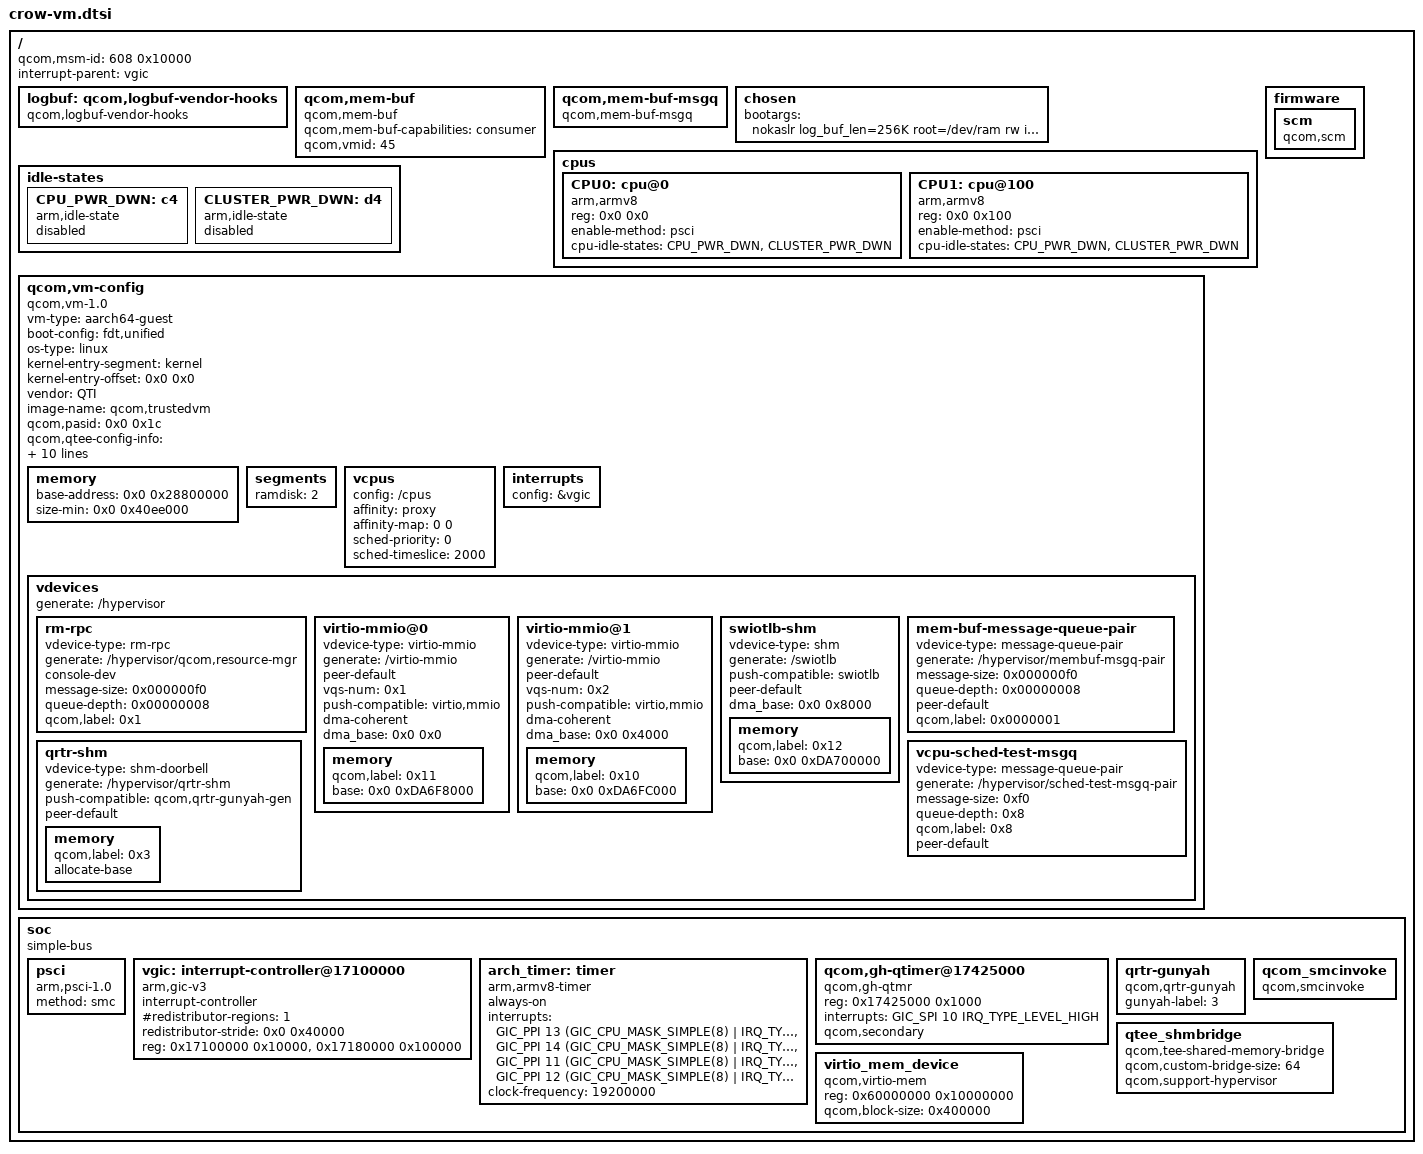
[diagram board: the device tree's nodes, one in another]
#include <dt-bindings/interrupt-controller/arm-gic.h>
#include <dt-bindings/clock/qcom,gcc-crow.h>
#include <dt-bindings/clock/qcom,rpmh.h>

/ {
	#address-cells = <0x2>;
	#size-cells = <0x2>;
	qcom,msm-id = <608 0x10000>;
	interrupt-parent = <&vgic>;

	logbuf: qcom,logbuf-vendor-hooks {
		compatible = "qcom,logbuf-vendor-hooks";
	};

	qcom,mem-buf {
		compatible = "qcom,mem-buf";
		qcom,mem-buf-capabilities = "consumer";
		qcom,vmid = <45>;
	};

	qcom,mem-buf-msgq {
		compatible = "qcom,mem-buf-msgq";
	};

	chosen {
		bootargs = "nokaslr log_buf_len=256K root=/dev/ram rw init=/init console=hvc0 loglevel=8";
	};

	cpus {
		#address-cells = <0x2>;
		#size-cells = <0x0>;

		CPU0: cpu@0 {
			compatible = "arm,armv8";
			reg = <0x0 0x0>;
			device_type = "cpu";
			enable-method = "psci";
			cpu-idle-states = <&CPU_PWR_DWN
					   &CLUSTER_PWR_DWN>;
		};

		CPU1: cpu@100 {
			compatible = "arm,armv8";
			reg = <0x0 0x100>;
			device_type = "cpu";
			enable-method = "psci";
			cpu-idle-states = <&CPU_PWR_DWN
					   &CLUSTER_PWR_DWN>;
		};
	};

	idle-states {
		CPU_PWR_DWN: c4 { /* Using Gold C4 latencies */
			compatible = "arm,idle-state";
			status = "disabled";
		};

		CLUSTER_PWR_DWN: d4 { /* C4+D4 */
			compatible = "arm,idle-state";
			status = "disabled";
		};
	};

	qcom,vm-config {
		compatible = "qcom,vm-1.0";
		vm-type = "aarch64-guest";
		boot-config = "fdt,unified";
		os-type = "linux";
		kernel-entry-segment = "kernel";
		kernel-entry-offset = <0x0 0x0>;
		vendor = "QTI";
		image-name = "qcom,trustedvm";
		qcom,pasid = <0x0 0x1c>;
		qcom,qtee-config-info = "p=39,77,78,7C,8F,97,FE,159,199,47E,7F1;";
		qcom,secdomain-ids = <45>;
		qcom,primary-vm-index = <0>;
		vm-uri = "vmuid/trusted-ui";
		vm-guid = "598085da-c516-5b25-a9c1-927a02819770";
		qcom,sensitive;

		iomemory-ranges = <0x0 0xae8f000 0x0 0xae8f000 0x0 0x1000 0x0>;

		/* For LEVM pored usecases is SE0, for SE0 we use gpii5
		 * and irq no is 625.
		 */
		gic-irq-ranges = <625 625>; /* PVM->SVM IRQ transfer */

		vm-attrs = "crash-fatal";

		memory {
			#address-cells = <0x2>;
			#size-cells = <0x0>;
			base-address = <0x0 0x28800000 >;
			size-min = <0x0 0x40ee000>;    /* 64 MB */
		};

		segments {
			ramdisk = <2>; /* 8MB */
		};

		vcpus {
			config = "/cpus";
			affinity = "proxy";
			affinity-map = <0 0>;
			sched-priority = <0>;       /* relative to PVM */
			sched-timeslice = <2000>;   /* in ms */
		};

		interrupts {
			config = &vgic;
		};

		vdevices {
			generate = "/hypervisor";
			rm-rpc {
				vdevice-type = "rm-rpc";
				generate = "/hypervisor/qcom,resource-mgr";
				console-dev;
				message-size = <0x000000f0>;
				queue-depth = <0x00000008>;
				qcom,label = <0x1>;
			};

			virtio-mmio@0 {
				vdevice-type = "virtio-mmio";
				generate = "/virtio-mmio";
				peer-default;
				vqs-num = <0x1>;
				push-compatible = "virtio,mmio";
				dma-coherent;
				dma_base = <0x0 0x0>;
				memory {
					qcom,label = <0x11>;			//for persist.img
					#address-cells = <0x2>;
					base = <0x0 0xDA6F8000>;
				};
			};

			virtio-mmio@1 {
				vdevice-type = "virtio-mmio";
				generate = "/virtio-mmio";
				peer-default;
				vqs-num = <0x2>;
				push-compatible = "virtio,mmio";
				dma-coherent;
				dma_base = <0x0 0x4000>;
				memory {
					qcom,label = <0x10>;			//for system.img
					#address-cells = <0x2>;
					base = <0x0 0xDA6FC000>;
				};
			};

			swiotlb-shm {
				vdevice-type = "shm";
				generate = "/swiotlb";
				push-compatible = "swiotlb";
				peer-default;
				dma_base = <0x0 0x8000>;
				memory {
					qcom,label = <0x12>;
					#address-cells = <0x2>;
					base = <0x0 0xDA700000>;
				};
			};

			mem-buf-message-queue-pair {
				vdevice-type = "message-queue-pair";
				generate = "/hypervisor/membuf-msgq-pair";
				message-size = <0x000000f0>;
				queue-depth = <0x00000008>;
				peer-default;
				qcom,label = <0x0000001>;
			};

			qrtr-shm {
				vdevice-type = "shm-doorbell";
				generate = "/hypervisor/qrtr-shm";
				push-compatible = "qcom,qrtr-gunyah-gen";
				peer-default;
				memory {
					qcom,label = <0x3>;
					allocate-base;
				};
			};

			vcpu-sched-test-msgq {
				vdevice-type = "message-queue-pair";
				generate = "/hypervisor/sched-test-msgq-pair";
				message-size = <0xf0>;
				queue-depth = <0x8>;
				qcom,label = <0x8>;
				peer-default;
			};

		};
	};

	firmware: firmware {
		scm {
			compatible = "qcom,scm";
		};
	};

	soc: soc { };
};

&soc {
	#address-cells = <1>;
	#size-cells = <1>;
	ranges = <0 0 0 0xffffffff>;
	compatible = "simple-bus";

	psci {
		compatible = "arm,psci-1.0";
		method = "smc";
	};

	vgic: interrupt-controller@17100000 {
		compatible = "arm,gic-v3";
		interrupt-controller;
		#interrupt-cells = <0x3>;
		#redistributor-regions = <1>;
		redistributor-stride = <0x0 0x40000>;
		reg = <0x17100000 0x10000>,     /* GICD */
		      <0x17180000 0x100000>;    /* GICR * 8 */
	};

	arch_timer: timer {
		compatible = "arm,armv8-timer";
		always-on;
		interrupts = <GIC_PPI 13 (GIC_CPU_MASK_SIMPLE(8) | IRQ_TYPE_LEVEL_LOW)>,
			     <GIC_PPI 14 (GIC_CPU_MASK_SIMPLE(8) | IRQ_TYPE_LEVEL_LOW)>,
			     <GIC_PPI 11 (GIC_CPU_MASK_SIMPLE(8) | IRQ_TYPE_LEVEL_LOW)>,
			     <GIC_PPI 12 (GIC_CPU_MASK_SIMPLE(8) | IRQ_TYPE_LEVEL_LOW)>;
		clock-frequency = <19200000>;
	};

	qcom,gh-qtimer@17425000 {
		compatible = "qcom,gh-qtmr";
		reg = <0x17425000 0x1000>;
		reg-names = "qtmr-base";
		interrupts = <GIC_SPI 10 IRQ_TYPE_LEVEL_HIGH>;
		interrupt-names = "qcom,qtmr-intr";
		qcom,secondary;
	};

	qrtr-gunyah {
		compatible = "qcom,qrtr-gunyah";
		gunyah-label = <3>;
	};

	qcom_smcinvoke {
		compatible = "qcom,smcinvoke";
	};

	qtee_shmbridge {
		compatible = "qcom,tee-shared-memory-bridge";
		qcom,custom-bridge-size = <64>;
		qcom,support-hypervisor;
	};

	virtio_mem_device {
		compatible = "qcom,virtio-mem";
		/* Must be memory_block_size_bytes() aligned */
		reg = <0x60000000 0x10000000>;
		qcom,block-size = <0x400000>;
	};
};

#include "msm-arm-smmu-crow-vm.dtsi"
#include "crow-vm-dma-heaps.dtsi"
